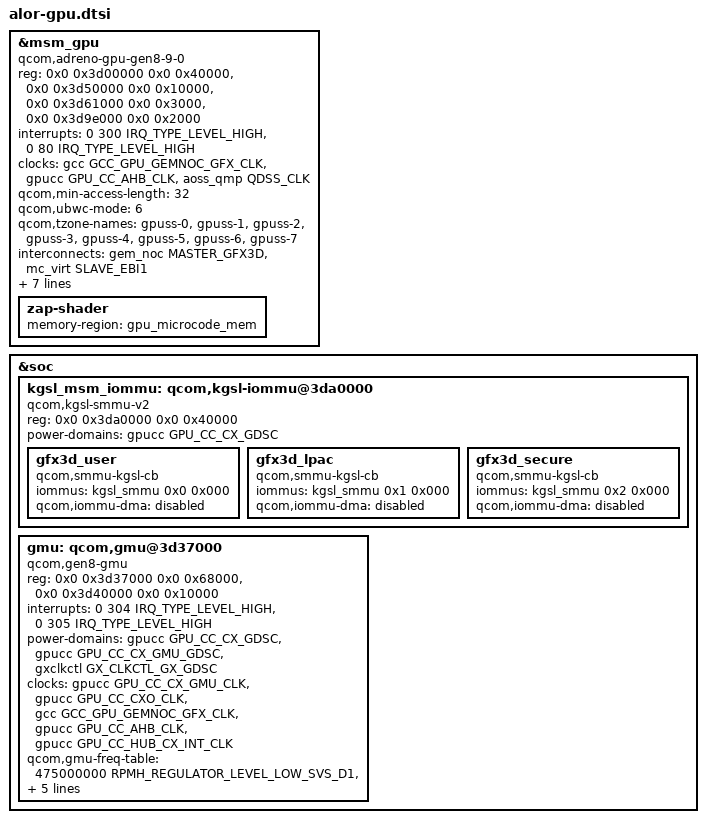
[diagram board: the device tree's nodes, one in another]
// SPDX-License-Identifier: BSD-3-Clause
/*
 * Copyright (c) Qualcomm Technologies, Inc. and/or its subsidiaries.
 */

#define MHZ_TO_KBPS(mhz, w) ((mhz * 1000000 * w) / (1024))

/* External feature codes */
#define FC_UNKNOWN 0x0

/* Pcodes */
#define PCODE_UNKNOWN 0

#define SKU_CODE(pcode, featurecode) ((pcode << 16) + featurecode)

&msm_gpu {
	compatible = "qcom,adreno-gpu-gen8-9-0", "qcom,kgsl-3d0";
	status = "ok";
	reg = <0x0 0x3d00000 0x0 0x40000>, <0x0 0x3d50000 0x0 0x10000>,
		<0x0 0x3d61000 0x0 0x3000>, <0x0 0x3d9e000 0x0 0x2000>;
	reg-names = "kgsl_3d0_reg_memory", "rscc", "cx_dbgc", "cx_misc";

	interrupts = <0 300 IRQ_TYPE_LEVEL_HIGH>, <0 80 IRQ_TYPE_LEVEL_HIGH>;
	interrupt-names = "kgsl_3d0_irq", "cx_host_irq";

	clocks = <&gcc GCC_GPU_GEMNOC_GFX_CLK>,
		<&gpucc GPU_CC_AHB_CLK>,
		<&aoss_qmp QDSS_CLK>;
	clock-names = "gcc_gpu_memnoc_gfx",
			"gpu_cc_ahb",
			"apb_pclk";

	qcom,min-access-length = <32>;

	qcom,ubwc-mode = <6>;

	qcom,tzone-names = "gpuss-0", "gpuss-1", "gpuss-2", "gpuss-3",
			"gpuss-4", "gpuss-5", "gpuss-6", "gpuss-7";

	interconnects = <&gem_noc MASTER_GFX3D &mc_virt SLAVE_EBI1>;
	interconnect-names = "gpu_icc_path";

	qcom,bus-table-cnoc =
		<0>,   /* Off */
		<100>; /* On */

	qcom,bus-table-ddr =
		<MHZ_TO_KBPS(0, 4)>,    /*           index=0  */
		<MHZ_TO_KBPS(547, 4)>,  /* LowSVS_D1 index=1  */
		<MHZ_TO_KBPS(1353, 4)>, /*    LowSVS index=2  */
		<MHZ_TO_KBPS(1555, 4)>, /*       SVS index=3  */
		<MHZ_TO_KBPS(1708, 4)>, /*       SVS index=4  */
		<MHZ_TO_KBPS(2092, 4)>, /*       SVS index=5  */
		<MHZ_TO_KBPS(2736, 4)>, /*       NOM index=6  */
		<MHZ_TO_KBPS(3187, 4)>, /*       NOM index=7  */
		<MHZ_TO_KBPS(3686, 4)>, /*     TURBO index=8  */
		<MHZ_TO_KBPS(4224, 4)>, /*  TURBO_L1 index=9 */
		<MHZ_TO_KBPS(4780, 4)>; /*  TURBO_L3 index=10 */

	zap-shader {
		memory-region = <&gpu_microcode_mem>;
	};
};

&soc {
	kgsl_msm_iommu: qcom,kgsl-iommu@3da0000 {
		compatible = "qcom,kgsl-smmu-v2";
		reg = <0x0 0x3da0000 0x0 0x40000>;

		power-domains = <&gpucc GPU_CC_CX_GDSC>;

		gfx3d_user: gfx3d_user {
			compatible = "qcom,smmu-kgsl-cb";
			iommus = <&kgsl_smmu 0x0 0x000>;
			qcom,iommu-dma = "disabled";
		};

		gfx3d_lpac: gfx3d_lpac {
			compatible = "qcom,smmu-kgsl-cb";
			iommus = <&kgsl_smmu 0x1 0x000>;
			qcom,iommu-dma = "disabled";
		};

		gfx3d_secure: gfx3d_secure {
			compatible = "qcom,smmu-kgsl-cb";
			iommus = <&kgsl_smmu 0x2 0x000>;
			qcom,iommu-dma = "disabled";
		};
	};

	gmu: qcom,gmu@3d37000 {
		compatible = "qcom,gen8-gmu";

		reg = <0x0 0x3d37000 0x0 0x68000>,
			<0x0 0x3d40000 0x0 0x10000>;

		reg-names = "gmu", "gmu_ao_blk_dec0";

		interrupts = <0 304 IRQ_TYPE_LEVEL_HIGH>,
			<0 305 IRQ_TYPE_LEVEL_HIGH>;
		interrupt-names = "hfi", "gmu";

		power-domains = <&gpucc GPU_CC_CX_GDSC>,
				<&gpucc GPU_CC_CX_GMU_GDSC>,
				<&gxclkctl GX_CLKCTL_GX_GDSC>;

		power-domain-names = "cx", "gmu_cx", "gx";

		clocks = <&gpucc GPU_CC_CX_GMU_CLK>,
			<&gpucc GPU_CC_CXO_CLK>,
			<&gcc GCC_GPU_GEMNOC_GFX_CLK>,
			<&gpucc GPU_CC_AHB_CLK>,
			<&gpucc GPU_CC_HUB_CX_INT_CLK>;

		clock-names = "gmu_clk", "cxo_clk",
			"memnoc_clk", "ahb_clk", "hub_clk";

		qcom,gmu-freq-table = <475000000 RPMH_REGULATOR_LEVEL_LOW_SVS_D1>,
					<700000000 RPMH_REGULATOR_LEVEL_SVS>;
		qcom,gmu-perf-ddr-bw = <MHZ_TO_KBPS(1555, 4)>;

		iommus = <&kgsl_smmu 0x5 0x000>;
		qcom,iommu-dma = "disabled";

		qcom,ipc-core = <0x0 0x01100000 0x0 0x3c0000>;
	};
};
